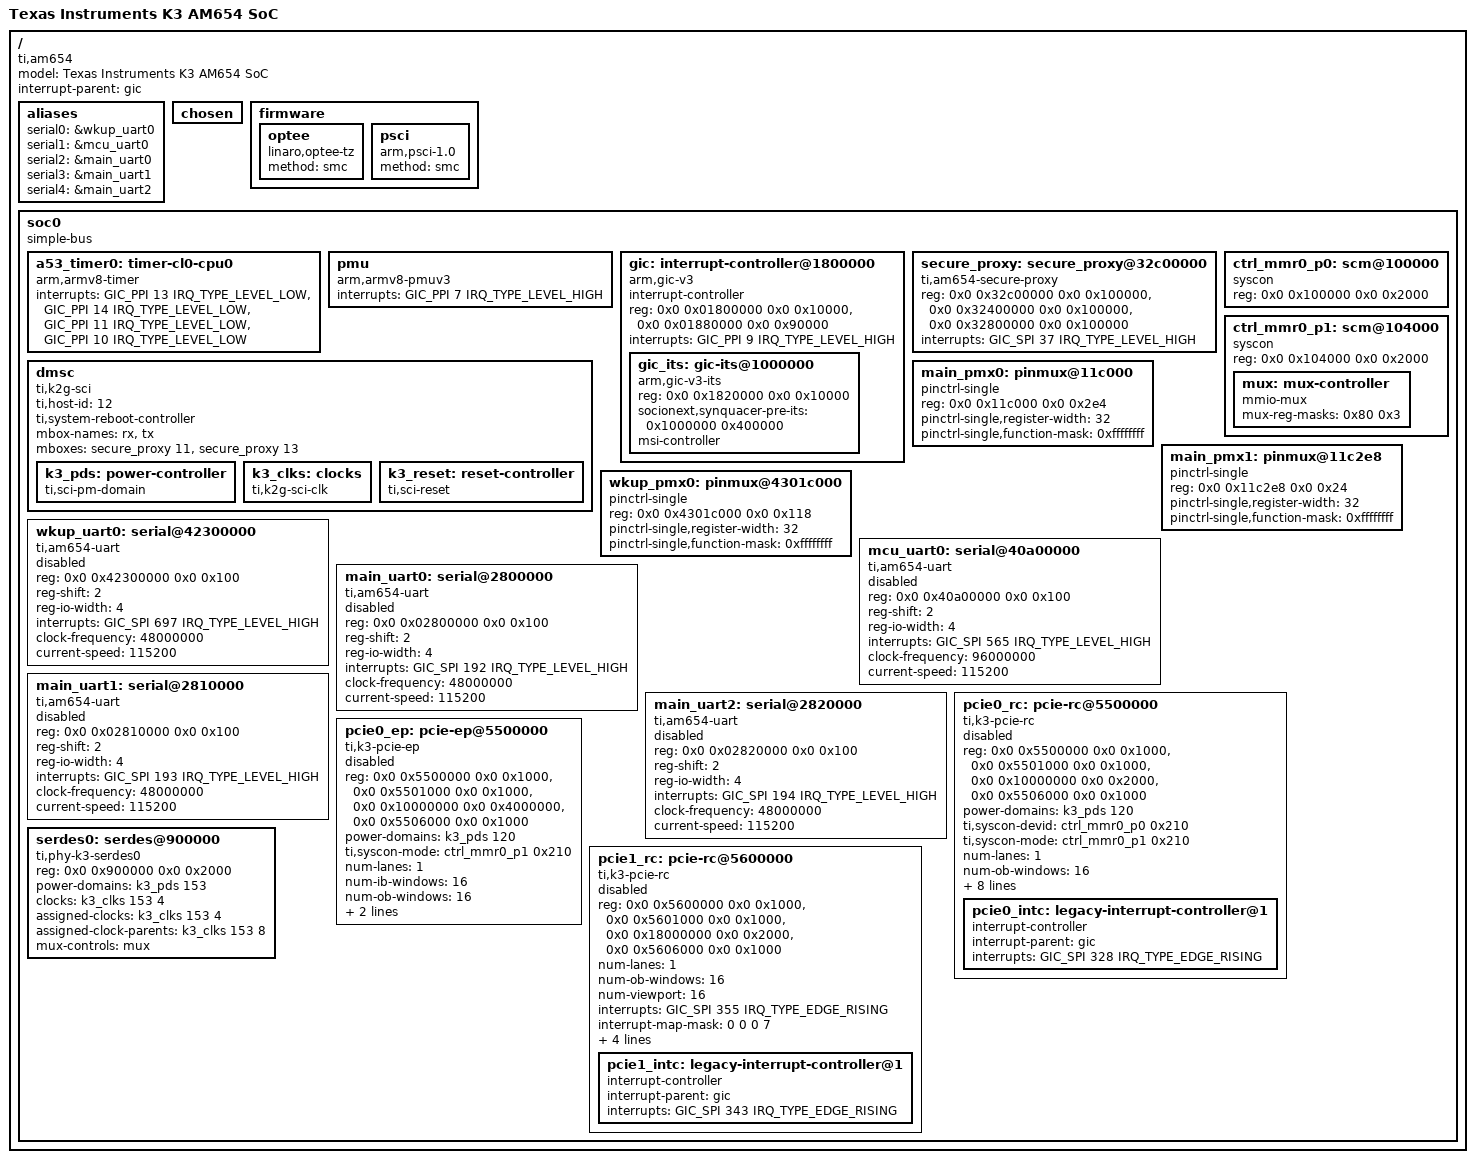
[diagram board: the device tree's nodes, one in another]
// SPDX-License-Identifier: GPL-2.0
/*
 * Device Tree Source for AM6 SoC Family
 *
 * Copyright (C) 2016-2018 Texas Instruments Incorporated - http://www.ti.com/
 */

#include <dt-bindings/gpio/gpio.h>
#include <dt-bindings/interrupt-controller/irq.h>
#include <dt-bindings/interrupt-controller/arm-gic.h>
#include <dt-bindings/pinctrl/k3-am6.h>
#include <dt-bindings/phy/phy.h>

/ {
	model = "Texas Instruments K3 AM654 SoC";
	compatible = "ti,am654";
	interrupt-parent = <&gic>;
	#address-cells = <2>;
	#size-cells = <2>;

	aliases {
		serial0 = &wkup_uart0;
		serial1 = &mcu_uart0;
		serial2 = &main_uart0;
		serial3 = &main_uart1;
		serial4 = &main_uart2;
	};

	chosen { };

	firmware {
		optee {
			compatible = "linaro,optee-tz";
			method = "smc";
		};

		psci: psci {
			compatible = "arm,psci-1.0";
			method = "smc";
		};
	};

	soc0: soc0 {
		compatible = "simple-bus";
		#address-cells = <2>;
		#size-cells = <2>;
		ranges;

		a53_timer0: timer-cl0-cpu0 {
			compatible = "arm,armv8-timer";
			interrupts = <GIC_PPI 13 IRQ_TYPE_LEVEL_LOW>, /* cntpsirq */
				     <GIC_PPI 14 IRQ_TYPE_LEVEL_LOW>, /* cntpnsirq */
				     <GIC_PPI 11 IRQ_TYPE_LEVEL_LOW>, /* cntvirq */
				     <GIC_PPI 10 IRQ_TYPE_LEVEL_LOW>; /* cnthpirq */
		};

		pmu: pmu {
			compatible = "arm,armv8-pmuv3";
			/* Recommendation from GIC500 TRM Table A.3 */
			interrupts = <GIC_PPI 7 IRQ_TYPE_LEVEL_HIGH>;
		};

		gic: interrupt-controller@1800000 {
			compatible = "arm,gic-v3";
			#address-cells = <2>;
			#size-cells = <2>;
			ranges;
			#interrupt-cells = <3>;
			interrupt-controller;
			/*
			 * NOTE: we are NOT gicv2 backward compat, so no GICC,
			 * GICH or GICV
			 */
			reg = <0x0 0x01800000 0x0 0x10000>,	/* GICD */
			      <0x0 0x01880000 0x0 0x90000>;	/* GICR */

			/*
			 * vcpumntirq:
			 * virtual CPU interface maintenance interrupt
			 */
			interrupts = <GIC_PPI 9 IRQ_TYPE_LEVEL_HIGH>;

			gic_its: gic-its@1000000 {
				compatible = "arm,gic-v3-its";
				reg = <0x0 0x1820000 0x0 0x10000>;
				socionext,synquacer-pre-its = <0x1000000 0x400000>;
				msi-controller;
				#msi-cells = <1>;
			};
		};

		secure_proxy: secure_proxy@32c00000 {
			compatible = "ti,am654-secure-proxy";
			#mbox-cells = <1>;
			reg-names = "target_data", "rt", "scfg";
			reg = <0x0 0x32c00000 0x0 0x100000>,
			      <0x0 0x32400000 0x0 0x100000>,
			      <0x0 0x32800000 0x0 0x100000>;
			interrupt-names = "rx_011";
			interrupts = <GIC_SPI 37 IRQ_TYPE_LEVEL_HIGH>;
		};

		dmsc: dmsc {
			compatible = "ti,k2g-sci";
			ti,host-id = <12>;
			#address-cells = <2>;
			#size-cells = <2>;
			ranges;
			/*
			 * In case of rare platforms that does not use am6 as
			 * system master, use /delete-property/
			 */
			ti,system-reboot-controller;
			mbox-names = "rx", "tx";

			mboxes= <&secure_proxy 11>,
				<&secure_proxy 13>;

			k3_pds: power-controller {
				compatible = "ti,sci-pm-domain";
				#power-domain-cells = <1>;
			};

			k3_clks: clocks {
				compatible = "ti,k2g-sci-clk";
				#clock-cells = <2>;
			};

			k3_reset: reset-controller {
				compatible = "ti,sci-reset";
				#reset-cells = <2>;
			};
		};

		ctrl_mmr0_p0: scm@100000 {
			compatible = "syscon";
			reg = <0x0 0x100000 0x0 0x2000>;
			#syscon-cells = <1>;
		};

		ctrl_mmr0_p1: scm@104000 {
			compatible = "syscon", "simple-mfd";
			reg = <0x0 0x104000 0x0 0x2000>;
			#syscon-cells = <1>;
			mux: mux-controller {
				compatible = "mmio-mux";
				#mux-control-cells = <0>;
				mux-reg-masks = <0x80 0x3>;
			};
		};

		main_pmx0: pinmux@11c000 {
			compatible = "pinctrl-single";
			reg = <0x0 0x11c000 0x0 0x2e4>;
			#pinctrl-cells = <1>;
			pinctrl-single,register-width = <32>;
			pinctrl-single,function-mask = <0xffffffff>;
		};

		main_pmx1: pinmux@11c2e8 {
			compatible = "pinctrl-single";
			reg = <0x0 0x11c2e8 0x0 0x24>;
			#pinctrl-cells = <1>;
			pinctrl-single,register-width = <32>;
			pinctrl-single,function-mask = <0xffffffff>;
		};

		wkup_pmx0: pinmux@4301c000 {
			compatible = "pinctrl-single";
			reg = <0x0 0x4301c000 0x0 0x118>;
			#pinctrl-cells = <1>;
			pinctrl-single,register-width = <32>;
			pinctrl-single,function-mask = <0xffffffff>;
		};

		wkup_uart0: serial@42300000 {
			compatible = "ti,am654-uart", "ti,omap4-uart", "ns16550a";
			reg = <0x0 0x42300000 0x0 0x100>;
			reg-shift = <2>;
			reg-io-width = <4>;
			interrupts = <GIC_SPI 697 IRQ_TYPE_LEVEL_HIGH>;
			clock-frequency = <48000000>;
			current-speed = <115200>;
			status = "disabled";
		};

		mcu_uart0: serial@40a00000 {
			compatible = "ti,am654-uart", "ti,omap4-uart", "ns16550a";
			reg = <0x0 0x40a00000 0x0 0x100>;
			reg-shift = <2>;
			reg-io-width = <4>;
			interrupts = <GIC_SPI 565 IRQ_TYPE_LEVEL_HIGH>;
			clock-frequency = <96000000>;
			current-speed = <115200>;
			status = "disabled";
		};

		main_uart0: serial@2800000 {
			compatible = "ti,am654-uart", "ti,omap4-uart", "ns16550a";
			reg = <0x0 0x02800000 0x0 0x100>;
			reg-shift = <2>;
			reg-io-width = <4>;
			interrupts = <GIC_SPI 192 IRQ_TYPE_LEVEL_HIGH>;
			clock-frequency = <48000000>;
			current-speed = <115200>;
			status = "disabled";
		};

		main_uart1: serial@2810000 {
			compatible = "ti,am654-uart", "ti,omap4-uart", "ns16550a";
			reg = <0x0 0x02810000 0x0 0x100>;
			reg-shift = <2>;
			reg-io-width = <4>;
			interrupts = <GIC_SPI 193 IRQ_TYPE_LEVEL_HIGH>;
			clock-frequency = <48000000>;
			current-speed = <115200>;
			status = "disabled";
		};

		main_uart2: serial@2820000 {
			compatible = "ti,am654-uart", "ti,omap4-uart", "ns16550a";
			reg = <0x0 0x02820000 0x0 0x100>;
			reg-shift = <2>;
			reg-io-width = <4>;
			interrupts = <GIC_SPI 194 IRQ_TYPE_LEVEL_HIGH>;
			clock-frequency = <48000000>;
			current-speed = <115200>;
			status = "disabled";
		};

                pcie0_rc: pcie-rc@5500000 {
                        compatible = "ti,k3-pcie-rc", "snps,dw-pcie-4.80";
                        reg =  <0x0 0x5500000 0x0 0x1000>, <0x0 0x5501000 0x0 0x1000>, <0x0 0x10000000 0x0 0x2000>, <0x0 0x5506000 0x0 0x1000>;
                        reg-names = "app", "dbics", "config", "atu";
			power-domains = <&k3_pds 120>;
                        #address-cells = <3>;
                        #size-cells = <2>;
                        ranges = <0x81000000 0 0          0x0   0x10002000 0 0x00010000
                                  0x82000000 0 0x10012000 0x0   0x10012000 0 0x3FEE000>;
                        ti,syscon-devid = <&ctrl_mmr0_p0 0x210>;
                        ti,syscon-mode = <&ctrl_mmr0_p1 0x210>;
                        status = "disabled";
                        device_type = "pci";
                        num-lanes = <1>;
                        num-ob-windows = <16>;
                        num-viewport = <16>;
			phys = <&serdes0 PHY_TYPE_PCIE 0>;
			phy-names = "pcie-phy0";
                        /* error interrupt */
                        interrupts = <GIC_SPI 340 IRQ_TYPE_EDGE_RISING>;
                        #interrupt-cells = <1>;
                        interrupt-map-mask = <0 0 0 7>;
                        interrupt-map = <0 0 0 1 &pcie0_intc 0>, /* INT A */
                                        <0 0 0 2 &pcie0_intc 0>, /* INT B */
                                        <0 0 0 3 &pcie0_intc 0>, /* INT C */
                                        <0 0 0 4 &pcie0_intc 0>; /* INT D */
                        msi-map = <0x0 &gic_its 0x0 0x1000>;

                        pcie0_intc: legacy-interrupt-controller@1 {
                                interrupt-controller;
                                #interrupt-cells = <1>;
                                interrupt-parent = <&gic>;
                                interrupts = <GIC_SPI 328 IRQ_TYPE_EDGE_RISING>;
                        };
                };

		pcie0_ep: pcie-ep@5500000 {
			compatible = "ti,k3-pcie-ep", "snps,dw-pcie-4.80";
			reg =  <0x0 0x5500000 0x0 0x1000>, <0x0 0x5501000 0x0 0x1000>, <0x0 0x10000000 0x0 0x4000000>, <0x0 0x5506000 0x0 0x1000>;
			reg-names = "app", "dbics", "addr_space", "atu";
			power-domains = <&k3_pds 120>;
                        ti,syscon-mode = <&ctrl_mmr0_p1 0x210>;
			status = "disabled";
			num-lanes = <1>;
			num-ib-windows = <16>;
			num-ob-windows = <16>;
			/* error interrupt */
			interrupts = <GIC_SPI 340 IRQ_TYPE_EDGE_RISING>;
			phys = <&serdes0 PHY_TYPE_PCIE 0>;
			phy-names = "pcie-phy0";
		};

                pcie1_rc: pcie-rc@5600000 {
                        compatible = "ti,k3-pcie-rc", "snps,dw-pcie-4.80";
                        reg =  <0x0 0x5600000 0x0 0x1000>, <0x0 0x5601000 0x0 0x1000>, <0x0 0x18000000 0x0 0x2000>, <0x0 0x5606000 0x0 0x1000>;
                        reg-names = "app", "dbics", "config", "atu";
                        #address-cells = <3>;
                        #size-cells = <2>;
                        ranges = <0x81000000 0 0          0x0   0x18002000 0 0x00010000
                                  0x82000000 0 0x18012000 0x0   0x18012000 0 0x3FEE000>;
                        //ti,syscon-dev = <&devctrl>;
                        status = "disabled";
                        device_type = "pci";
                        num-lanes = <1>;
                        num-ob-windows = <16>;
                        num-viewport = <16>;
                        /* error interrupt */
                        interrupts = <GIC_SPI 355 IRQ_TYPE_EDGE_RISING>;
                        #interrupt-cells = <1>;
                        interrupt-map-mask = <0 0 0 7>;
                        interrupt-map = <0 0 0 1 &pcie1_intc 0>, /* INT A */
                                        <0 0 0 2 &pcie1_intc 0>, /* INT B */
                                        <0 0 0 3 &pcie1_intc 0>, /* INT C */
                                        <0 0 0 4 &pcie1_intc 0>; /* INT D */
                        msi-map = <0x0 &gic_its 0x0 0x1000>;

                        pcie1_intc: legacy-interrupt-controller@1 {
                                interrupt-controller;
                                #interrupt-cells = <1>;
                                interrupt-parent = <&gic>;
                                interrupts = <GIC_SPI 343 IRQ_TYPE_EDGE_RISING>;
                        };
                };

		serdes0: serdes@900000 {
			compatible = "ti,phy-k3-serdes0";
			reg = <0x0 0x900000 0x0 0x2000>;
                        reg-names = "serdes";
			#phy-cells = <2>;
			power-domains = <&k3_pds 153>;
			clocks = <&k3_clks 153 4>;
			clock-names = "fck";
			assigned-clocks = <&k3_clks 153 4>;
			assigned-clock-parents = <&k3_clks 153 8>;
			mux-controls = <&mux>;
		};
	};
};
